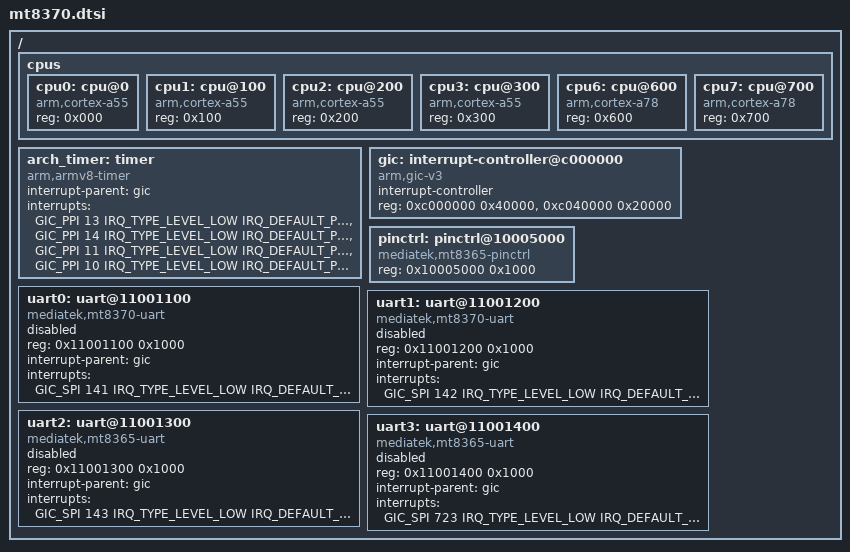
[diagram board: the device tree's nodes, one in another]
// SPDX-License-Identifier: GPL-2.0+
/*
 * Copyright (c) 2025 MediaTek Inc.
 *
 */

#include <arm64/armv8-a.dtsi>
#include <zephyr/dt-bindings/interrupt-controller/arm-gic.h>
#include <zephyr/dt-bindings/interrupt-controller/mtk-irq.h>


/ {
	#address-cells = <1>;
	#size-cells = <1>;

	cpus {
		#address-cells = <1>;
		#size-cells = <0>;

		cpu0: cpu@0 {
			device_type = "cpu";
			compatible = "arm,cortex-a55";
			reg = <0x000>;
		};

		cpu1: cpu@100 {
			device_type = "cpu";
			compatible = "arm,cortex-a55";
			reg = <0x100>;
		};

		cpu2: cpu@200 {
			device_type = "cpu";
			compatible = "arm,cortex-a55";
			reg = <0x200>;
		};

		cpu3: cpu@300 {
			device_type = "cpu";
			compatible = "arm,cortex-a55";
			reg = <0x300>;
		};

		cpu6: cpu@600 {
			device_type = "cpu";
			compatible = "arm,cortex-a78";
			reg = <0x600>;
		};

		cpu7: cpu@700 {
			device_type = "cpu";
			compatible = "arm,cortex-a78";
			reg = <0x700>;
		};
    };

	arch_timer: timer {
		compatible = "arm,armv8-timer";
		interrupt-parent = <&gic>;
		interrupts = <GIC_PPI 13 IRQ_TYPE_LEVEL_LOW IRQ_DEFAULT_PRIORITY>,
			     <GIC_PPI 14 IRQ_TYPE_LEVEL_LOW IRQ_DEFAULT_PRIORITY>,
			     <GIC_PPI 11 IRQ_TYPE_LEVEL_LOW IRQ_DEFAULT_PRIORITY>,
			     <GIC_PPI 10 IRQ_TYPE_LEVEL_LOW IRQ_DEFAULT_PRIORITY>;
	};

	gic: interrupt-controller@c000000 {
		compatible = "arm,gic-v3", "arm,gic";
		#interrupt-cells = <4>;
		interrupt-controller;
		reg = <0xc000000 0x40000>,
		      <0xc040000 0x20000>;
		status = "okay";
	};

	pinctrl: pinctrl@10005000 {
		compatible = "mediatek,mt8365-pinctrl";
		reg = <0x10005000 0x1000>;
		#address-cells = <1>;
		#size-cells = <0>;
	    status = "okay";
    };

	uart0: uart@11001100 {
		compatible = "mediatek,mt8370-uart";
		reg = <0x11001100 0x1000>;
		interrupt-parent = <&gic>;
		interrupts = <GIC_SPI 141 IRQ_TYPE_LEVEL_LOW IRQ_DEFAULT_PRIORITY>;
		status = "disabled";
	};

	uart1: uart@11001200 {
		compatible = "mediatek,mt8370-uart";
		reg = <0x11001200 0x1000>;
		interrupt-parent = <&gic>;
		interrupts = <GIC_SPI 142 IRQ_TYPE_LEVEL_LOW IRQ_DEFAULT_PRIORITY>;
		status = "disabled";
	};

	uart2: uart@11001300 {
		compatible = "mediatek,mt8365-uart";
		reg = <0x11001300 0x1000>;
		interrupt-parent = <&gic>;
		interrupts = <GIC_SPI 143 IRQ_TYPE_LEVEL_LOW IRQ_DEFAULT_PRIORITY>;
		status = "disabled";
	};

	uart3: uart@11001400 {
		compatible = "mediatek,mt8365-uart";
		reg = <0x11001400 0x1000>;
		interrupt-parent = <&gic>;
		interrupts = <GIC_SPI 723 IRQ_TYPE_LEVEL_LOW IRQ_DEFAULT_PRIORITY>;
		status = "disabled";
	};
};
